# V8M_Generic register map
Vendor: ARM Ltd.; Series: M; File version: 2020-08-22T15:13:24.354567-05:00
CPU: CM4 r0p0, little endian, vendor SysTick, 8 interrupt priority bits
Registers are 32-bit, read-write, no defined reset value unless marked. A register's access mark holds for its fields unless they carry their own. Offsets are from the block's base; [hi:lo] are bit positions; {n}, {i} and the like mark numbered series; 'fields as' and 'values as' point back to an identical list.

## SCB — System Control Block
Base 0xE000ED00
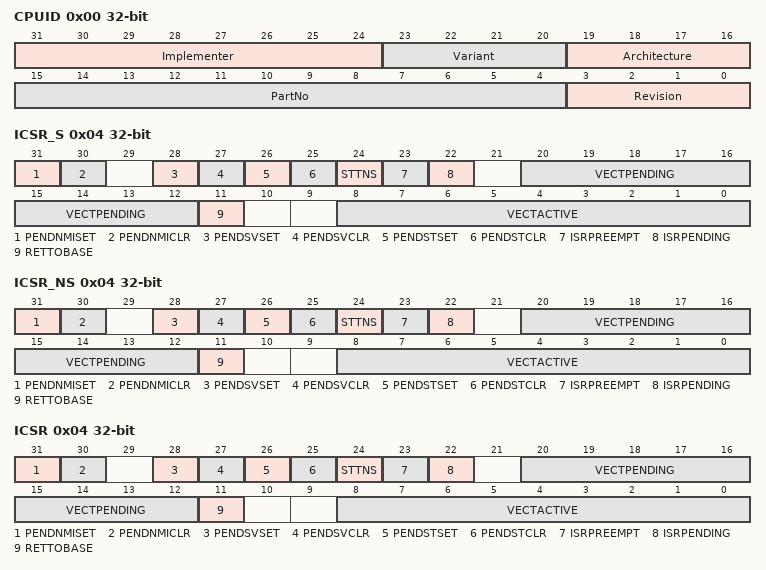
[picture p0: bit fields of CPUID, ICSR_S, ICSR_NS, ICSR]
0x00 CPUID ro — Provides identification information for the PE, including an implementer code for the device and a device ID number
  [31:24] Implementer — Implementer code
    65=_A_ARM_Limited; Not 0x41=Implementer_other_than_ARM_Limited
  [23:20] Variant — Variant number
  [19:16] Architecture — Architecture version
    12=ARMv8_M_architecture_without_Main_Extension; 15=ARMv8_M_architecture_with_Main_Extension
  [15:4] PartNo — Part number
  [3:0] Revision — Revision number
0x04 ICSR_S — Controls and provides status information for NMI, PendSV, SysTick and interrupts
  [31] PENDNMISET
    0=No_effect; 1=Sets_the_NMI_exception_pending
  [30] PENDNMICLR — Pend NMI clear
    0=No_effect; 1=Clear_pending_status
  [28] PENDSVSET — Pend PendSV set
    0=No_effect; 1=Sets_the_PendSV_exception_pending
  [27] PENDSVCLR — Pend PendSV clear
    0=No_effect; 1=Clear_pending_status
  [26] PENDSTSET — Pend SysTick set
    0=No_effect; 1=Sets_the_SysTick_exception_FTSSS_pending
  [25] PENDSTCLR — Pend SysTick clear
    0=No_effect; 1=Clear_pending_status
  [24] STTNS — SysTick Targets Non-secure
    0=SysTick_is_Secure; 1=SysTick_is_Non_secure
  [23] ISRPREEMPT — Interrupt preempt
    0=Will_not_service; 1=Will_service_a_pending_exception
  [22] ISRPENDING — Interrupt pending
    0=No_external_interrupt_pending; 1=External_interrupt_pending
  [20:12] VECTPENDING — Vector pending
    Zero=No_pending_and_enabled_exception; Non zero=Exception_number
  [11] RETTOBASE — Return to base
    0=There_is_more_than_one_active_exception; 1=There_is_only_one_active_exception
  [8:0] VECTACTIVE — Vector active
    Zero=Thread_mode; Non zero=Exception_number
0x04 ICSR_NS — Controls and provides status information for NMI, PendSV, SysTick and interrupts
  fields as ICSR_S
0x04 ICSR — Controls and provides status information for NMI, PendSV, SysTick and interrupts
  fields as ICSR_S
0x08 VTOR_S — Holds the vector table address FTSSS
  [31:7] TBLOFF — Table offset
0x08 VTOR_NS — Holds the vector table address FTSSS
  [31:7] TBLOFF — Table offset
0x08 VTOR — Holds the vector table address FTSSS
  [31:7] TBLOFF — Table offset
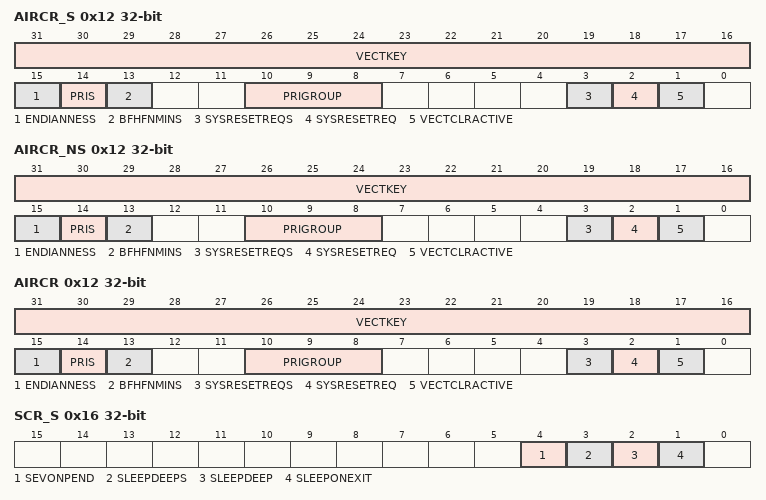
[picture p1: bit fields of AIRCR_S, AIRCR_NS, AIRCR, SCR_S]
0x12 AIRCR_S — Sets or returns interrupt control and reset configuration
  [31:16] VECTKEY — Vector key
    0x5FA=Permit_write_to_AIRCR_fields; Not 0x05FA=Accompanying_write_to_AIRCR_fields_ignored
  [15] ENDIANNESS — Data endianness
    0=Little_endian; 1=Big_endian
  [14] PRIS — Prioritize Secure exceptions
    0=Priority_ranges_of_Secure_and_Non_secure_exceptions_are_identical; 1=Non_secure_exceptions_are_de_prioritized
  [13] BFHFNMINS — BusFault, HardFault, and NMI Non-secure enable
    0=BusFault_HardFault_and_NMI_are_Secure; 1=BusFault_and_NMI_are_Non_secure_and_exceptions_can_target_Non_secure_HardFault
  [10:8] PRIGROUP — Priority grouping
    0=Group_priority_7_1_subpriority_0; {v}=Group_priority_7_{v+1}_subpriority_{v}_0 (v=1..5); 6=Group_priority_7_subpriority_6_0; 7=No_group_priority_subpriority_7_0
  [3] SYSRESETREQS — System reset request Secure only
    0=SYSRESETREQ_functionality_is_available_to_both_Security_states; 1=SYSRESETREQ_functionality_is_only_available_to_Secure_state
  [2] SYSRESETREQ — System reset request
    0=Do_not_request_a_system_reset; 1=Request_a_system_reset
  [1] VECTCLRACTIVE — Clear active state
    0=Do_not_clear_active_state; 1=Clear_active_state
0x12 AIRCR_NS — Sets or returns interrupt control and reset configuration
  fields as AIRCR_S
0x12 AIRCR — Sets or returns interrupt control and reset configuration
  fields as AIRCR_S
0x16 SCR_S — Sets or returns system control data
  [4] SEVONPEND — Send event on pend
    0=Transitions_from_inactive_to_pending_are_not_wakeup_events; 1=Transitions_from_inactive_to_pending_are_wakeup_events
  [3] SLEEPDEEPS — Sleep deep secure
    0=The_SLEEPDEEP_bit_accessible_from_both_Security_states; 1=The_SLEEPDEEP_bit_behaves_as_RAZ_WI_when_accessed_from_the_Non_secure_state
  [2] SLEEPDEEP
    0=Selected_sleep_state_is_not_deep_sleep; 1=Selected_sleep_state_is_deep_sleep
  [1] SLEEPONEXIT
    0=Enter_sleep_state_disabled; 1=Enter_sleep_state_permitted
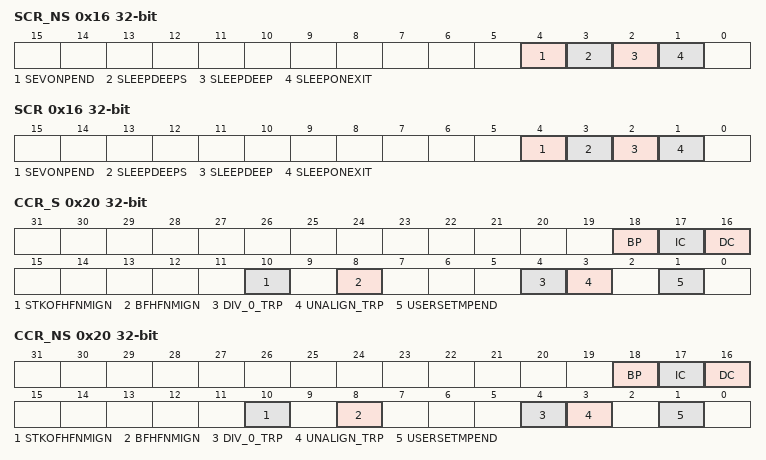
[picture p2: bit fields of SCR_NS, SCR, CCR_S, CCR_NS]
0x16 SCR_NS — Sets or returns system control data
  fields as SCR_S
0x16 SCR — Sets or returns system control data
  fields as SCR_S
0x20 CCR_S — Sets or returns configuration and control data
  [18] BP — Branch prediction enable
    0=Program_flow_prediction_disabled_FTSSS; 1=Program_flow_prediction_enabled_FTSSS
  [17] IC — Instruction cache enable
    0=Instruction_caches_disabled_FTSSS; 1=Instruction_caches_enabled_FTSSS
  [16] DC — Data cache enable
    0=Data_caching_disabled_FTSSS; 1=Data_caching_enabled_FTSSS
  [10] STKOFHFNMIGN — Stack overflow in HardFault and NMI ignore
    0=Stack_limit_faults_not_ignored; 1=Stack_limit_faults_at_requested_priorities_of_less_than_0_ignored
  [8] BFHFNMIGN — BusFault in HardFault or NMI ignore
    0=Precise_BusFaults_not_ignored; 1=Precise_BusFaults_at_requested_priorities_of_less_than_0_ignored
  [4] DIV_0_TRP — Divide by zero trap
    0=DIVBYZERO_UsageFault_generation_disabled; 1=DIVBYZERO_UsageFault_generation_enabled
  [3] UNALIGN_TRP — Unaligned trap
    0=Unaligned_accesses_permitted_from_LDR_LDRH_STR_and_STRH; 1=Any_unaligned_transaction_generates_an_UNALIGNED_UsageFault
  [1] USERSETMPEND — User set main pending
    0=Unprivileged_accesses_to_the_STIR_generate_a_fault; 1=Unprivileged_accesses_to_the_STIR_are_permitted
0x20 CCR_NS — Sets or returns configuration and control data
  fields as CCR_S
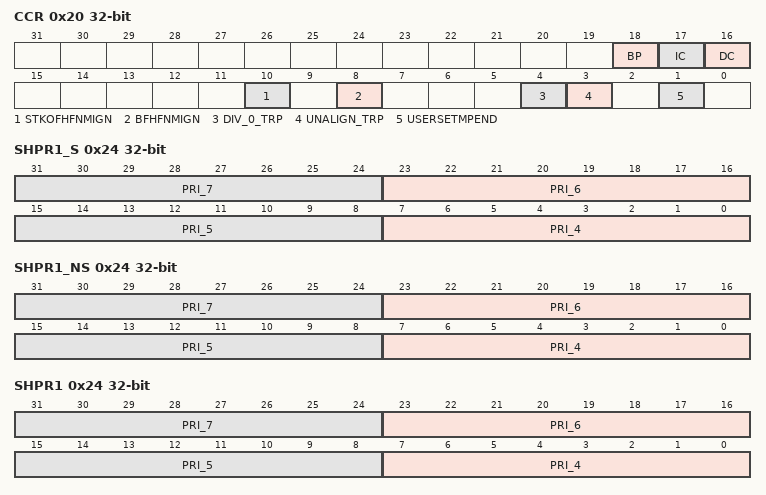
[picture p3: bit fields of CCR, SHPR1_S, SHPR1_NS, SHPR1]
0x20 CCR — Sets or returns configuration and control data
  fields as CCR_S
0x24 SHPR1_S — Sets or returns priority for system handlers 4 - 7
  [8n-25:8n-32] PRI_{n} (n=4..7) — Priority {n}
0x24 SHPR1_NS — Sets or returns priority for system handlers 4 - 7
  [8n-25:8n-32] PRI_{n} (n=4..7) — Priority {n}
0x24 SHPR1 — Sets or returns priority for system handlers 4 - 7
  [8n-25:8n-32] PRI_{n} (n=4..7) — Priority {n}
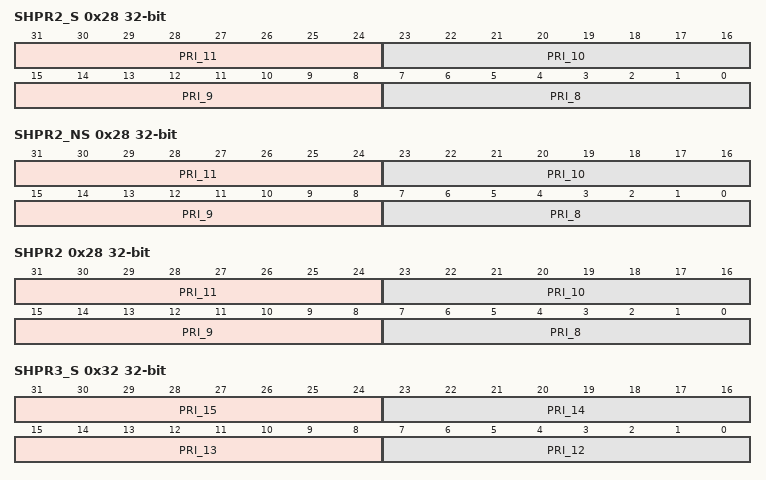
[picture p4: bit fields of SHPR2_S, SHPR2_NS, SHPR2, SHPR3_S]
0x28 SHPR2_S — Sets or returns priority for system handlers 8 - 11
  [31:24] PRI_11 — Priority 11
  [23:16] PRI_10
  [15:8] PRI_9
  [7:0] PRI_8
0x28 SHPR2_NS — Sets or returns priority for system handlers 8 - 11
  fields as SHPR2_S
0x28 SHPR2 — Sets or returns priority for system handlers 8 - 11
  fields as SHPR2_S
0x32 SHPR3_S — Sets or returns priority for system handlers 12 - 15
  [31:24] PRI_15 — Priority 15
  [23:16] PRI_14 — Priority 14
  [15:8] PRI_13
  [7:0] PRI_12 — Priority 12
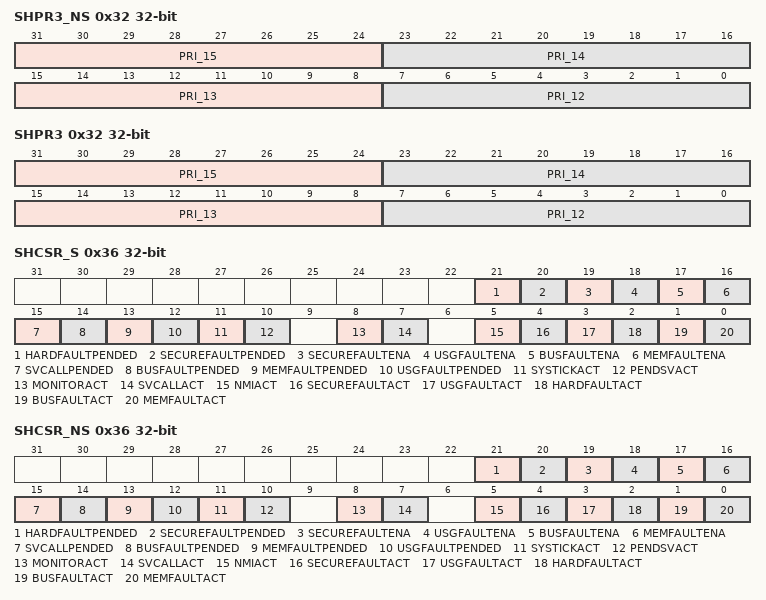
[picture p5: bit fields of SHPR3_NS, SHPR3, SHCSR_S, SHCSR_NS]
0x32 SHPR3_NS — Sets or returns priority for system handlers 12 - 15
  fields as SHPR3_S
0x32 SHPR3 — Sets or returns priority for system handlers 12 - 15
  fields as SHPR3_S
0x36 SHCSR_S — Provides access to the active and pending status of system exceptions
  [21] HARDFAULTPENDED — HardFault exception pended state
    0=HardFault_exception_not_pending_FTSSS; 1=HardFault_exception_pending_FTSSS
  [20] SECUREFAULTPENDED — SecureFault exception pended state
    0=SecureFault_exception_not_pending; 1=SecureFault_exception_pending
  [19] SECUREFAULTENA — SecureFault exception enable
    0=SecureFault_exception_disabled; 1=SecureFault_exception_enabled
  [18] USGFAULTENA — UsageFault exception enable
    0=UsageFault_exception_disabled_FTSSS; 1=UsageFault_exception_enabled_FTSSS
  [17] BUSFAULTENA — BusFault exception enable
    0=BusFault_exception_disabled; 1=BusFault_exception_enabled
  [16] MEMFAULTENA — MemManage exception enable
    0=MemManage_exception_disabled_FTSSS; 1=MemManage_exception_enabled_FTSSS
  [15] SVCALLPENDED — SVCall exception pended state
    0=SVCall_exception_not_pending_FTSSS; 1=SVCall_exception_pending_FTSSS
  [14] BUSFAULTPENDED — BusFault exception pended state
    0=BusFault_exception_not_pending; 1=BusFault_exception_pending
  [13] MEMFAULTPENDED — MemManage exception pended state
    0=MemManage_exception_not_pending_FTSSS; 1=MemManage_exception_pending_FTSSS
  [12] USGFAULTPENDED — UsageFault exception pended state
    0=UsageFault_exception_not_pending_FTSSS; 1=UsageFault_exception_pending_FTSSS
  [11] SYSTICKACT — SysTick exception active state
    0=SysTick_exception_not_active_FTSSS; 1=SysTick_exception_active_FTSSS
  [10] PENDSVACT — PendSV exception active state
    0=PendSV_exception_not_active_FTSSS; 1=PendSV_exception_active_FTSSS
  [8] MONITORACT — DebugMonitor exception active state
    0=DebugMonitor_exception_not_active; 1=DebugMonitor_exception_active
  [7] SVCALLACT — SVCall exception active state
    0=SVCall_exception_not_active_FTSSS; 1=SVCall_exception_active_FTSSS
  [5] NMIACT — NMI exception active state
    0=NMI_exception_not_active; 1=NMI_exception_active
  [4] SECUREFAULTACT — SecureFault exception active state
    0=SecureFault_exception_not_active; 1=SecureFault_exception_active
  [3] USGFAULTACT — UsageFault exception active state FTSSS
    0=UsageFault_exception_not_active_FTSSS; 1=UsageFault_exception_active_FTSSS
  [2] HARDFAULTACT — HardFault exception active state
    0=HardFault_exception_not_active_FTSSS; 1=HardFault_exception_active_FTSSS
  [1] BUSFAULTACT — BusFault exception active state
    0=BusFault_exception_not_active; 1=BusFault_exception_active
  [0] MEMFAULTACT — MemManage exception active state FTSSS
    0=MemManage_exception_not_active_FTSSS; 1=MemManage_exception_active_FTSSS
0x36 SHCSR_NS — Provides access to the active and pending status of system exceptions
  fields as SHCSR_S
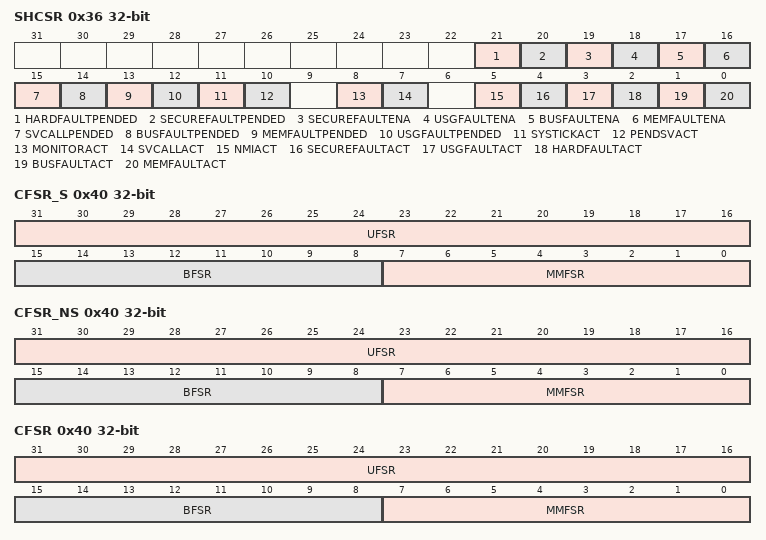
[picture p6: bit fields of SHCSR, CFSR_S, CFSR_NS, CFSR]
0x36 SHCSR — Provides access to the active and pending status of system exceptions
  fields as SHCSR_S
0x40 CFSR_S — Contains the three Configurable Fault Status Registers
  [31:16] UFSR — UsageFault Status Register
  [15:8] BFSR — BusFault Status Register
  [7:0] MMFSR — MemManage Fault Status Register
0x40 CFSR_NS — Contains the three Configurable Fault Status Registers
  fields as CFSR_S
0x40 CFSR — Contains the three Configurable Fault Status Registers
  fields as CFSR_S
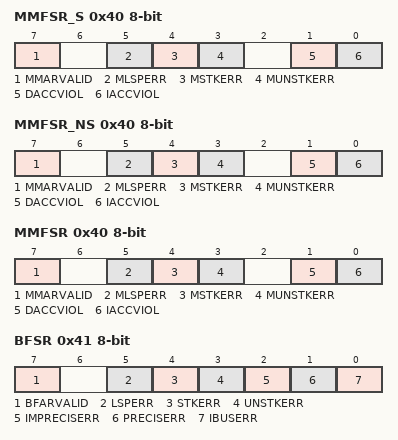
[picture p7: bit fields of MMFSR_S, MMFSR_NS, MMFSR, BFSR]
0x40 MMFSR_S 8-bit — Shows the status of MPU faults
  [7] MMARVALID — MMFAR valid flag
    0=MMFAR_content_not_valid; 1=MMFAR_content_valid
  [5] MLSPERR — MemManage lazy state preservation error flag
    0=No_MemManage_occurred; 1=MemManage_occurred
  [4] MSTKERR — MemManage stacking error flag
    0=No_derived_MemManage_occurred; 1=Derived_MemManage_occurred_during_exception_entry
  [3] MUNSTKERR — MemManage unstacking error flag
    0=No_derived_MemManage_fault_occurred; 1=Derived_MemManage_fault_occurred_during_exception_return
  [1] DACCVIOL — Data access violation flag
    0=No_MemManage_fault_on_data_access_has_occurred; 1=MemManage_fault_on_data_access_has_occurred
  [0] IACCVIOL — Instruction access violation
    0=No_MemManage_fault_on_instruction_access_has_occurred; 1=MemManage_fault_on_instruction_access_has_occurred
0x40 MMFSR_NS 8-bit — Shows the status of MPU faults
  fields as MMFSR_S
0x40 MMFSR 8-bit — Shows the status of MPU faults
  fields as MMFSR_S
0x41 BFSR 8-bit — Shows the status of bus errors resulting from instruction fetches and data accesses
  [7] BFARVALID
    0=BFAR_content_not_valid; 1=BFAR_content_valid
  [5] LSPERR — Lazy state preservation error
    0=No_BusFault_occurred; 1=BusFault_occurred
  [4] STKERR — Stack error
    0=No_derived_BusFault_occurred; 1=Derived_BusFault_occurred_during_exception_entry
  [3] UNSTKERR — Unstack error
    0=No_derived_BusFault_occurred; 1=Derived_BusFault_occurred_during_exception_return
  [2] IMPRECISERR — Imprecise error
    0=No_imprecise_data_access_error_has_occurred; 1=Imprecise_data_access_error_has_occurred
  [1] PRECISERR — Precise error
    0=No_precise_data_access_error_has_occurred; 1=Precise_data_access_error_has_occurred
  [0] IBUSERR — Instruction bus error
    0=No_BusFault_on_instruction_prefetch_has_occurred; 1=A_BusFault_on_an_instruction_prefetch_has_occurred
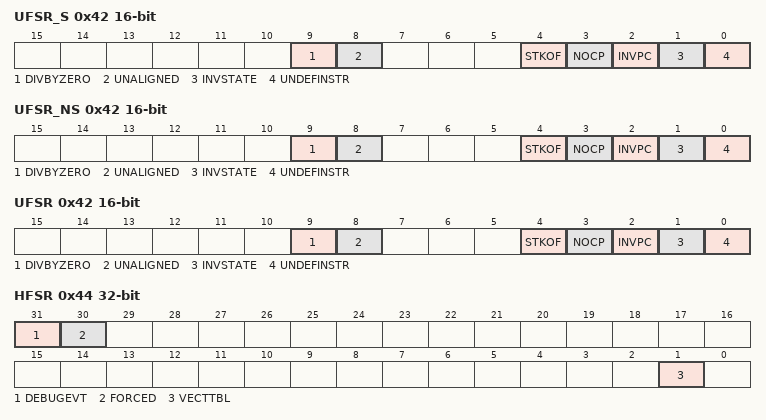
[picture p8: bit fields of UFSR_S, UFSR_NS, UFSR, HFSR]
0x42 UFSR_S 16-bit — Contains the status for some instruction execution faults, and for data access faults
  [all] fields
    0=Error_has_not_occurred; 1=Error_has_occurred
  [9] DIVBYZERO — Divide by zero flag
  [8] UNALIGNED — Unaligned access flag
  [4] STKOF — Stack overflow flag
  [3] NOCP — No coprocessor flag
  [2] INVPC — Invalid PC flag
  [1] INVSTATE — Invalid state flag
  [0] UNDEFINSTR — Undefined instruction flag
0x42 UFSR_NS 16-bit — Contains the status for some instruction execution faults, and for data access faults
  fields as UFSR_S
0x42 UFSR 16-bit — Contains the status for some instruction execution faults, and for data access faults
  fields as UFSR_S
0x44 HFSR — Shows the cause of any HardFaults
  [31] DEBUGEVT — Debug event
    0=No_debug_event_has_occurred; 1=Debug_event_has_occurred
  [30] FORCED
    0=No_priority_escalation_has_occurred; 1=Processor_has_escalated_a_configurable_priority_exception_to_HardFault
  [1] VECTTBL — Vector table
    0=No_vector_table_read_fault_has_occurred; 1=Vector_table_read_fault_has_occurred
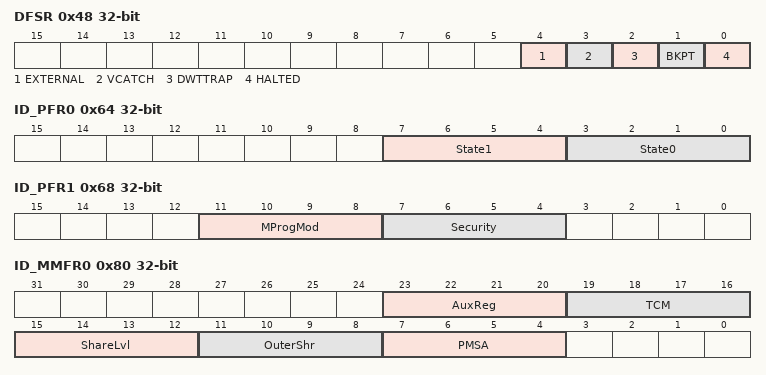
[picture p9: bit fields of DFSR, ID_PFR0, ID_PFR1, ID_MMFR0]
0x48 DFSR — Shows which debug event occurred
  [all] fields
    0=Debug_event_has_not_occurred; 1=Debug_event_has_occurred
  [4] EXTERNAL — External event
  [3] VCATCH — Vector Catch event
  [2] DWTTRAP — Watchpoint event
  [1] BKPT — Breakpoint event
  [0] HALTED — Halt or step event
0x52 MMFAR_S — Shows the address of the memory location that caused an MPU fault
  [31:0] ADDRESS — Data address for an MemManage fault
0x52 MMFAR_NS — Shows the address of the memory location that caused an MPU fault
  [31:0] ADDRESS — Data address for an MemManage fault
0x52 MMFAR — Shows the address of the memory location that caused an MPU fault
  [31:0] ADDRESS — Data address for an MemManage fault
0x56 BFAR — Shows the address associated with a precise data access BusFault
  [31:0] ADDRESS — Data address for a precise BusFault
0x60 AFSR — Provides IMPLEMENTATION DEFINED fault status information
0x64 ID_PFR0 ro — Gives top-level information about the instruction set supported by the PE
  [7:4] State1 — State one
    3=T32_instruction_set_including_Thumb_2_Technology_implemented
  [3:0] State0 — State two
    0=A32_instruction_set_not_implemented
0x68 ID_PFR1 ro — Gives information about the programmers' model and Extensions support
  [11:8] MProgMod — M programmers' model
    2=Two_stack_programmers_model
  [7:4] Security
    0=Security_Extension_not_implemented; 1=Security_Extension_implemented
0x72 ID_DFR0 ro — Provides top level information about the debug system
  [23:20] MProfDbg — M-profile debug
    0=Halting_Debug_is_not_implemented; 2=ARMv8_M_Debug_architecture
0x76 ID_AFR0 ro — Provides information about the IMPLEMENTATION DEFINED features of the PE
0x80 ID_MMFR0 ro — Provides information about the implemented memory model and memory management support
  [23:20] AuxReg — Auxiliary Registers
    0=No_Auxiliary_Control_Registers; 1=Auxiliary_Control_Registers_supported
  [19:16] TCM — Tightly coupled memories
    0=None_supported; 1=TCMs_supported_with_IMPLEMENTATION_DEFINED_control
  [15:12] ShareLvl — Shareability Levels
    0=One_level_of_shareability_implemented; 1=Two_levels_of_shareability_implemented
  [11:8] OuterShr — Outermost Shareability
    0=Implemented_as_Non_cacheable; 1=Implemented_with_hardware_coherency_support; 15=Shareability_ignored
  [7:4] PMSA — Protected memory system architecture
    4=Supports_PMSAv8
0x84 ID_MMFR1 ro — Provides information about the implemented memory model and memory management support
0x88 ID_MMFR2 ro — Provides information about the implemented memory model and memory management support
  [27:24] WFIStall
    0=WFI_never_stalls; 1=WFI_has_the_ability_to_stall
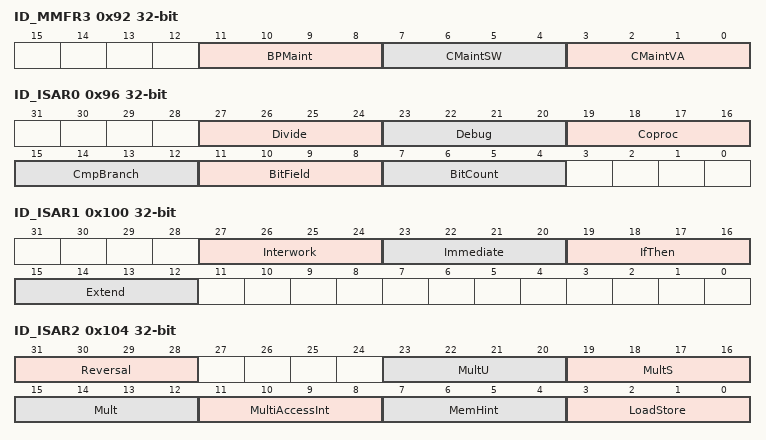
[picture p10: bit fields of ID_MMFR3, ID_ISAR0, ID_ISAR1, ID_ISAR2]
0x92 ID_MMFR3 ro — Provides information about the implemented memory model and memory management support
  [11:8] BPMaint — Branch predictor maintenance
    0=None_supported; 1=Support_for_invalidate_all_of_branch_predictors
  [7:4] CMaintSW — Cache maintenance set/way
    0=None_supported; 1=Maintenance_by_set_way_operations_supported
  [3:0] CMaintVA — Cache maintenance by address
    0=None_supported; 1=Maintenance_by_address_and_instruction_cache_invalidate_all_supported
0x96 ID_ISAR0 ro — Provides information about the instruction set implemented by the PE
  [27:24] Divide
    1=Supports_SDIV_and_UDIV_instructions
  [23:20] Debug
    1=Supports_BKPT_instruction
  [19:16] Coproc — Coprocessor
    0=No_coprocessor_instructions_support_other_than_FPU; 4=Coprocessor_instructions_supported
  [15:12] CmpBranch — Compare and branch
    1=Supports_CBNZ_and_CBZ_instructions
  [11:8] BitField
    1=BFC_BFI_SBFX_and_UBFX_supported
  [7:4] BitCount
    1=CLZ_supported
0x100 ID_ISAR1 ro — Provides information about the instruction set implemented by the PE
  [27:24] Interwork — Interworking
    2=BLX_BX_and_loads_to_PC_interwork
  [23:20] Immediate
    2=ADDW_MOVW_MOVT_and_SUBW_supported
  [19:16] IfThen
    1=IT_instruction_supported
  [15:12] Extend
    1=SXTB_SXTH_UXTB_and_UXTH; 2=Adds_SXTB16_SXTAB_SXTAB16_SXTAH_UXTB16_UXTAB_UXTAB16_and_UXTAH_DSP_Extension_only
0x104 ID_ISAR2 ro — Provides information about the instruction set implemented by the PE
  [31:28] Reversal
    2=REV_REV16_REVSH_and_RBIT_instructions_supported
  [23:20] MultU — Multiply unsigned
    1=UMULL_and_UMLAL; 2=Adds_UMAAL_DSP_Extension_only
  [19:16] MultS — Multiply signed
    1=SMULL_and_SMLAL; 3=Adds_all_saturating_and_DSP_signed_multiplies_DSP_Extension_only
  [15:12] Mult — Multiplies
    2=MUL_MLA_and_MLS
  [11:8] MultiAccessInt — Multi-access instructions
    0=No_support; 1=LDM_and_STM_instructions_are_restartable; 2=LDM_and_STM_instructions_are_continuable
  [7:4] MemHint — Memory hints
    3=PLI_and_PLD_instructions_implemented
  [3:0] LoadStore
    2=Supports_load_acquire_store_release_and_exclusive_load_and_store_instructions
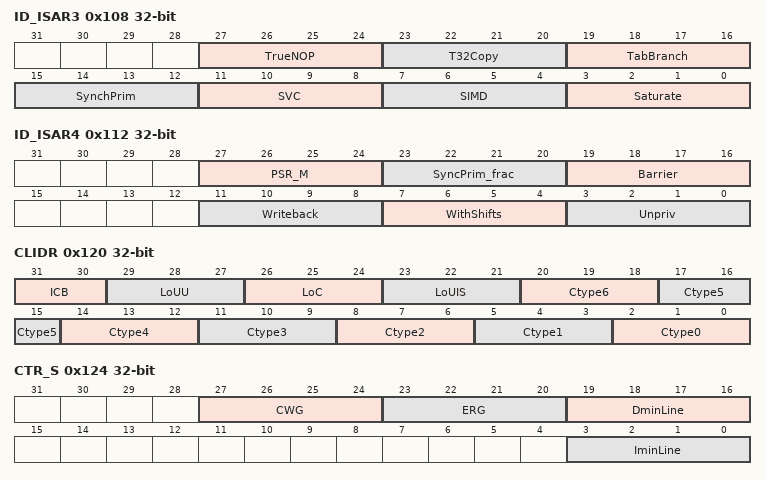
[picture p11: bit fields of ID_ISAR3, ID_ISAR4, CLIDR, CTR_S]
0x108 ID_ISAR3 ro — Provides information about the instruction set implemented by the PE
  [27:24] TrueNOP — True no-operation
    1=NOP_instruction_and_compatible_hints_implemented
  [23:20] T32Copy
    1=Encoding_T1_of_MOV_register_supports_copying_low_register_to_low_register
  [19:16] TabBranch — Table branch
    1=TBB_and_TBH_implemented
  [15:12] SynchPrim — Synchronization primitives
    1=LDREX_STREX_LDREXB_STREXB_LDREXH_STREXH_and_CLREX_implemented
  [11:8] SVC — Supervisor call
    1=SVC_instruction_implemented
  [7:4] SIMD — Single-instruction, multiple-data
    1=SSAT_USAT_and_Q_bit_implemented; 3=Adds_all_packed_arithmetic_and_GE_bits_DSP_Extension_only
  [3:0] Saturate
    0=None_implemented; 1=QADD_QDADD_QDSUB_QSUB_and_Q_bit_implemented_DSP_Extension_only
0x112 ID_ISAR4 ro — Provides information about the instruction set implemented by the PE
  [27:24] PSR_M — Program status registers M
    1=M_profile_forms_of_CPS_MRS_and_MSR_implemented
  [23:20] SyncPrim_frac — Synchronization primitives fractional
    3=LDREX_STREX_CLREX_LDREXB_LDREXH_STREXB_and_STREXH_implemented
  [19:16] Barrier
    1=DMB_DSB_and_ISB_barrier_instructions_implemented
  [11:8] Writeback
    1=All_writeback_addressing_modes_supported
  [7:4] WithShifts
    3=Support_for_constant_shifts_on_load_store_and_other_instructions
  [3:0] Unpriv — Unprivileged
    2=LDRBT_LDRHT_LDRSBT_LDRSHT_LDRT_STRBT_STRHT_and_STRT_implemented
0x116 ID_ISAR5 ro — Provides information about the instruction set implemented by the PE
0x120 CLIDR ro — Identifies the type of caches implemented and the level of coherency and unification
  [31:30] ICB — Inner cache boundary
    0=Not_disclosed_in_this_mechanism; 1=L1_cache_is_the_highest_inner_level; 2=L2_cache_is_the_highest_inner_level; 3=L3_cache_is_the_highest_inner_level
  [29:27] LoUU — Level of Unification Uniprocessor
  [26:24] LoC — Level of Coherence
  [23:21] LoUIS — Level of Unification Inner Shareable
  [3n+2:3n] Ctype{n} (n=0..6) — Cache type field {n}
    0=No_cache; 1=Instruction_cache_only; 2=Data_cache_only; 3=Separate_instruction_and_data_caches; 4=Unified_cache
0x124 CTR_S ro — Provides information about the architecture of the caches. CTR is RES0 if CLIDR is zero.
  [27:24] CWG — Cache Writeback Granule
    0=Indicates_that_this_register_does_not_provide_Cache_Writeback_Granule_information_and_either_the_architectural_maximum_of_512_words_2KB_must_be_assumed_or_the_Cache_Writeback_Granule_can_be_determined_from_maximum_cache_line_size_encoded_in_the_Cache_Size_ID_Registers; 0b0001-0b1000=Log2_of_the_number_of_words
  [23:20] ERG — Exclusives Reservation Granule
    0=Indicates_that_this_register_does_not_provide_Exclusives_Reservation_Granule_information_and_the_architectural_maximum_of_512_words_2KB_must_be_assumed; 0b0001-0b1000=Log2_of_the_number_of_words
  [19:16] DminLine — Data cache minimum line length
  [3:0] IminLine — Instruction cache minimum line length
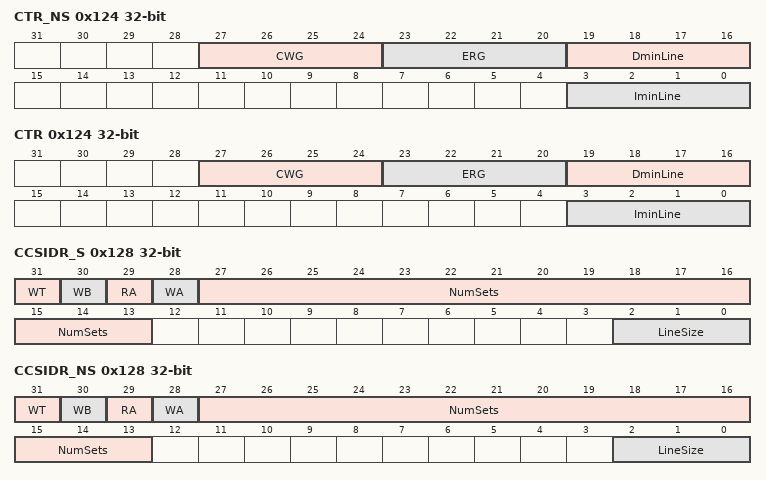
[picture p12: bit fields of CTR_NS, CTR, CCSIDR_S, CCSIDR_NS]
0x124 CTR_NS ro — Provides information about the architecture of the caches. CTR is RES0 if CLIDR is zero.
  fields as CTR_S
0x124 CTR ro — Provides information about the architecture of the caches. CTR is RES0 if CLIDR is zero.
  fields as CTR_S
0x128 CCSIDR_S ro — The CCSIDR provides information about the architecture of the currently selected cache
  [31] WT — Write-through
    0=Not_supported; 1=Supported
  [30] WB — Writeback
    0=Not_supported; 1=Supported
  [29] RA — Read-allocate
    0=Not_supported; 1=Supported
  [28] WA — Write-allocate
    0=Not_supported; 1=Supported
  [27:13] NumSets — Number of sets
  [2:0] LineSize
0x128 CCSIDR_NS ro — The CCSIDR provides information about the architecture of the currently selected cache
  fields as CCSIDR_S
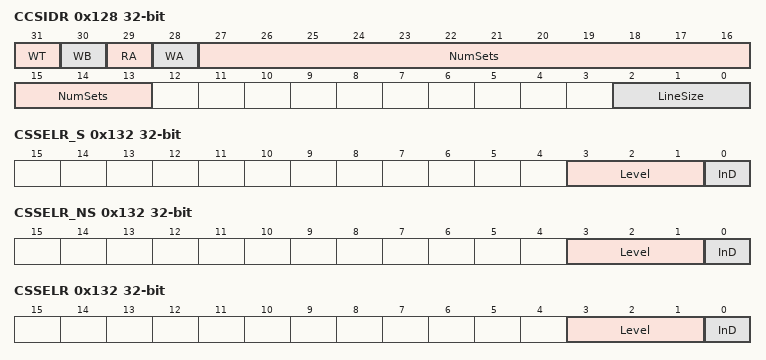
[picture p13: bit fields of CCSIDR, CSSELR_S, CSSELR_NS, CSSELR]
0x128 CCSIDR ro — The CCSIDR provides information about the architecture of the currently selected cache
  fields as CCSIDR_S
0x132 CSSELR_S — Selects the current Cache Size ID Register, CCSIDR, by specifying the required cache level and the cache type (either instruction or data cache)
  [3:1] Level — Cache level
    {v}=Level_{v+1}_cache (v=0..6)
  [0] InD — Instruction not data
    0=Data_or_unified_cache; 1=Instruction_cache
0x132 CSSELR_NS — Selects the current Cache Size ID Register, CCSIDR, by specifying the required cache level and the cache type (either instruction or data cache)
  fields as CSSELR_S
0x132 CSSELR — Selects the current Cache Size ID Register, CCSIDR, by specifying the required cache level and the cache type (either instruction or data cache)
  fields as CSSELR_S
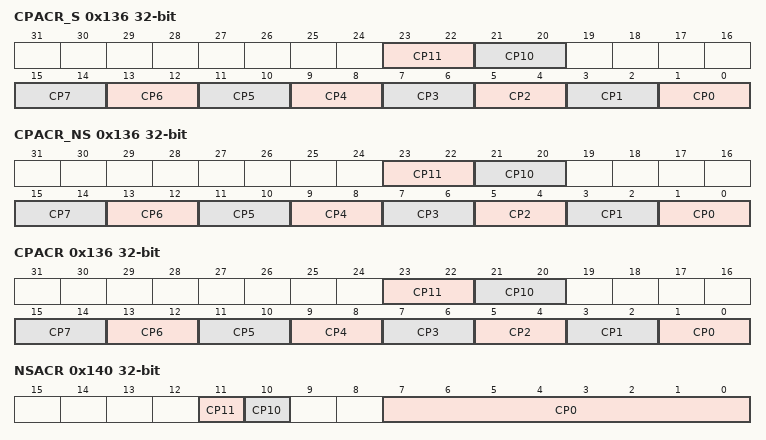
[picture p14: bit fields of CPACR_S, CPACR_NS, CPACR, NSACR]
0x136 CPACR_S — Specifies the access privileges for coprocessors and the FP Extension
  [23:22] CP11 — CP11 Privilege
  [21:20] CP10 — CP10 Privilege
    0=All_accesses_to_the_FP_Extension_result_in_NOCP_UsageFault; 1=Unprivileged_accesses_to_the_FP_Extension_result_in_NOCP_UsageFault; 3=Full_access_to_the_FP_Extension
  [2n+1:2n] CP{n} (n=0..7) — Coprocessor {n} privilege
    0=Access_denied; 1=Privileged_access_only; 3=Full_access
0x136 CPACR_NS — Specifies the access privileges for coprocessors and the FP Extension
  fields as CPACR_S
0x136 CPACR — Specifies the access privileges for coprocessors and the FP Extension
  fields as CPACR_S
0x140 NSACR — Defines the Non-secure access permissions for both the FP Extension and coprocessors CP0 to CP7
  [11] CP11 — CP11 access
  [10] CP10 — CP10 access
    0=Non_secure_accesses_to_the_Floating_point_Extension_generate_a_NOCP_UsageFault; 1=Non_secure_access_to_the_Floating_point_Extension_permitted
  [7:0] CP0 — CP0 access
    0=Non_secure_accesses_to_this_coprocessor_generate_a_NOCP_UsageFault; 1=Non_secure_access_to_this_coprocessor_permitted
